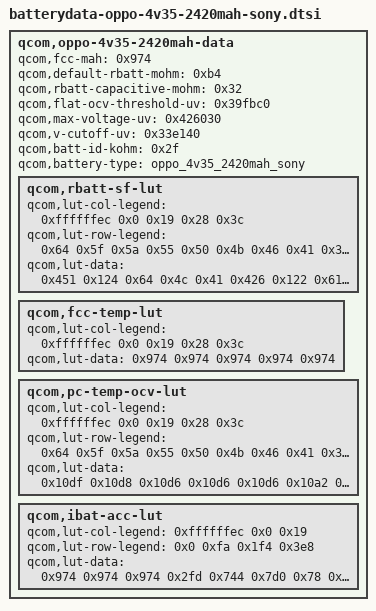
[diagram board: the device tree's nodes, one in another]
/* Copyright (c) 2020, The Linux Foundation. All rights reserved.
*  Copyright (c) 2020, the_shahnawaz_sheikh (sheikhshahnawaz41299).
*
* This program is free software; you can redistribute it and/or modify
* it under the terms of the GNU General Public License version 2 and
* only version 2 as published by the Free Software Foundation.
*
* This program is distributed in the hope that it will be useful,
* but WITHOUT ANY WARRANTY; without even the implied warranty of
* MERCHANTABILITY or FITNESS FOR A PARTICULAR PURPOSE.  See the
* GNU General Public License for more details.
*/
		qcom,oppo-4v35-2420mah-data {
			qcom,fcc-mah = <0x974>;
			qcom,default-rbatt-mohm = <0xb4>;
			qcom,rbatt-capacitive-mohm = <0x32>;
			qcom,flat-ocv-threshold-uv = <0x39fbc0>;
			qcom,max-voltage-uv = <0x426030>;
			qcom,v-cutoff-uv = <0x33e140>;
			qcom,batt-id-kohm = <0x2f>;
			qcom,battery-type = "oppo_4v35_2420mah_sony";

			qcom,rbatt-sf-lut {
				qcom,lut-col-legend = <0xffffffec 0x0 0x19 0x28 0x3c>;
				qcom,lut-row-legend = <0x64 0x5f 0x5a 0x55 0x50 0x4b 0x46 0x41 0x3c 0x37 0x32 0x2d 0x28 0x23 0x1e 0x19 0x14 0x10 0xd 0xb 0xa 0x9 0x8 0x7 0x6 0x5 0x4 0x3 0x2 0x1 0x0>;
				qcom,lut-data = <0x451 0x124 0x64 0x4c 0x41 0x426 0x122 0x61 0x4c 0x42 0x3f2 0x119 0x61 0x4c 0x41 0x3cd 0x117 0x64 0x4c 0x43 0x3bc 0x114 0x66 0x51 0x45 0x3b8 0x11d 0x67 0x4f 0x43 0x3b0 0x116 0x6c 0x53 0x46 0x3ac 0x119 0x70 0x56 0x48 0x3a9 0x119 0x72 0x55 0x4b 0x3aa 0x10f 0x6b 0x51 0x46 0x3b3 0x108 0x66 0x4c 0x42 0x3be 0x112 0x67 0x4c 0x44 0x3ca 0x119 0x67 0x4f 0x48 0x3e9 0x11a 0x66 0x53 0x49 0x40c 0x12c 0x6b 0x51 0x45 0x43d 0x13a 0x6a 0x4e 0x44 0x47d 0x146 0x6a 0x4e 0x44 0x4c6 0x156 0x6b 0x4c 0x44 0x50a 0x16c 0x6d 0x4e 0x44 0x567 0x181 0x6f 0x52 0x46 0x58d 0x191 0x73 0x55 0x47 0x5bd 0x1a3 0x7a 0x53 0x49 0x5f2 0x1b6 0x7f 0x58 0x4a 0x630 0x1c8 0x83 0x58 0x4c 0x640 0x1e3 0x84 0x56 0x4b 0x6a4 0x203 0x87 0x56 0x4b 0x708 0x235 0x8e 0x58 0x4e 0x76c 0x274 0x99 0x63 0x53 0x7d0 0x2e2 0xab 0x65 0x5a 0x1388 0x3e8 0xe8 0x7e 0x6a 0x21053 0x1e80c 0xe6cf 0x144 0xd0>;
			};

			qcom,fcc-temp-lut {
				qcom,lut-col-legend = <0xffffffec 0x0 0x19 0x28 0x3c>;
				qcom,lut-data = <0x974 0x974 0x974 0x974 0x974>;
			};

			qcom,pc-temp-ocv-lut {
				qcom,lut-col-legend = <0xffffffec 0x0 0x19 0x28 0x3c>;
				qcom,lut-row-legend = <0x64 0x5f 0x5a 0x55 0x50 0x4b 0x46 0x41 0x3c 0x37 0x32 0x2d 0x28 0x23 0x1e 0x19 0x14 0x10 0xd 0xb 0xa 0x9 0x8 0x7 0x6 0x5 0x4 0x3 0x2 0x1 0x0>;
				qcom,lut-data = <0x10df 0x10d8 0x10d6 0x10d6 0x10d6 0x10a2 0x109c 0x10a1 0x10a4 0x109a 0x1065 0x106a 0x106d 0x1072 0x105d 0x102f 0x103f 0x1042 0x1045 0x1032 0xffd 0x100b 0x100f 0x1013 0x1000 0xfcc 0xfd6 0xfe0 0xfd8 0xfd0 0xf94 0xfa2 0xfab 0xfac 0xf9b 0xf6d 0xf7e 0xf85 0xf86 0xf75 0xf3e 0xf57 0xf5f 0xf5f 0xf4f 0xf1a 0xf28 0xf33 0xf34 0xf22 0xefe 0xf05 0xf0d 0xf0d 0xf00 0xee9 0xef0 0xef0 0xef4 0xee9 0xed9 0xede 0xede 0xee2 0xed7 0xece 0xed0 0xecf 0xed3 0xec7 0xec5 0xec9 0xec3 0xec5 0xeb1 0xeba 0xebe 0xeaf 0xeaf 0xe8f 0xea5 0xea2 0xe9a 0xe95 0xe7a 0xe8d 0xe82 0xe7e 0xe78 0xe5f 0xe7a 0xe74 0xe68 0xe64 0xe4d 0xe6d 0xe6d 0xe64 0xe63 0xe4a 0xe68 0xe6c 0xe63 0xe61 0xe47 0xe60 0xe69 0xe5e 0xe5b 0xe45 0xe56 0xe61 0xe59 0xe57 0xe40 0xe46 0xe54 0xe4e 0xe4d 0xe36 0xe36 0xe36 0xe33 0xe37 0xe1d 0xe0e 0xe07 0xe07 0xe0e 0xdf7 0xddb 0xdca 0xdd0 0xddd 0xdc8 0xd98 0xd77 0xd87 0xd9d 0xd8b 0xd41 0xcfe 0xd24 0xd44 0xd3e 0xcc0 0xc86 0xc86 0xcc6 0xcce 0xbb8 0xbb8 0xbb8 0xbb8 0xbb8>;
			};

			qcom,ibat-acc-lut {
				qcom,lut-col-legend = <0xffffffec 0x0 0x19>;
				qcom,lut-row-legend = <0x0 0xfa 0x1f4 0x3e8>;
				qcom,lut-data = <0x974 0x974 0x974 0x2fd 0x744 0x7d0 0x78 0x668 0x7c6 0x0 0x4ce 0x778>;
			};
		};

